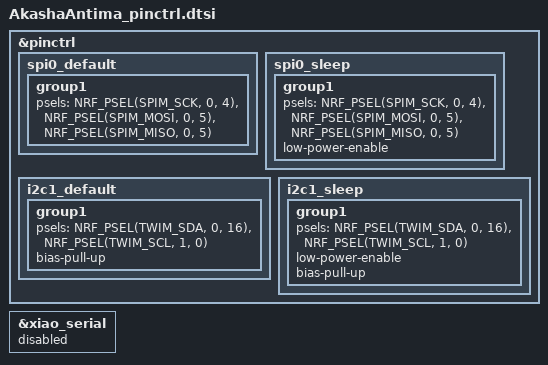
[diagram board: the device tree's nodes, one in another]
&pinctrl {
    spi0_default: spi0_default {
        group1 {
            psels = <NRF_PSEL(SPIM_SCK, 0, 4)>,
                    <NRF_PSEL(SPIM_MOSI, 0, 5)>,
                    <NRF_PSEL(SPIM_MISO, 0, 5)>;
        };
    };

    spi0_sleep: spi0_sleep {
        group1 {
            psels = <NRF_PSEL(SPIM_SCK, 0, 4)>,
                    <NRF_PSEL(SPIM_MOSI, 0, 5)>,
                    <NRF_PSEL(SPIM_MISO, 0, 5)>;
            low-power-enable;
        };
    };

    i2c1_default: i2c1_default {
        group1 {
            psels = <NRF_PSEL(TWIM_SDA, 0, 16)>,
                    <NRF_PSEL(TWIM_SCL, 1,  0)>;
            bias-pull-up;
        };
    };
      
    i2c1_sleep: i2c1_sleep {
        group1 {
            psels = <NRF_PSEL(TWIM_SDA, 0, 16)>,
                    <NRF_PSEL(TWIM_SCL, 1,  0)>;
            low-power-enable;
            bias-pull-up;
        };
    };
};

&xiao_serial { status = "disabled"; };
